VERSION ""

NS_ :

BS_:

BU_:

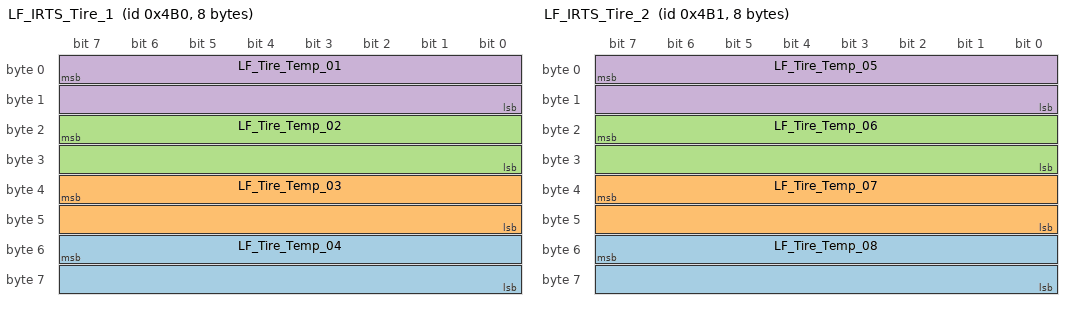
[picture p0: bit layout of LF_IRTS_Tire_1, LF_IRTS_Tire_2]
BO_ 1200 LF_IRTS_Tire_1: 8 Vector__XXX
 SG_ LF_Tire_Temp_04 : 55|16@0+ (0.1,-100) [-100|6453.5] "°C" Vector__XXX
 SG_ LF_Tire_Temp_03 : 39|16@0+ (0.1,-100) [-100|6453.5] "°C" Vector__XXX
 SG_ LF_Tire_Temp_02 : 23|16@0+ (0.1,-100) [-100|6453.5] "°C" Vector__XXX
 SG_ LF_Tire_Temp_01 : 7|16@0+ (0.1,-100) [-100|6453.5] "°C" Vector__XXX

BO_ 1201 LF_IRTS_Tire_2: 8 Vector__XXX
 SG_ LF_Tire_Temp_08 : 55|16@0+ (0.1,-100) [-100|6453.5] "°C" Vector__XXX
 SG_ LF_Tire_Temp_07 : 39|16@0+ (0.1,-100) [-100|6453.5] "°C" Vector__XXX
 SG_ LF_Tire_Temp_06 : 23|16@0+ (0.1,-100) [-100|6453.5] "°C" Vector__XXX
 SG_ LF_Tire_Temp_05 : 7|16@0+ (0.1,-100) [-100|6453.5] "°C" Vector__XXX

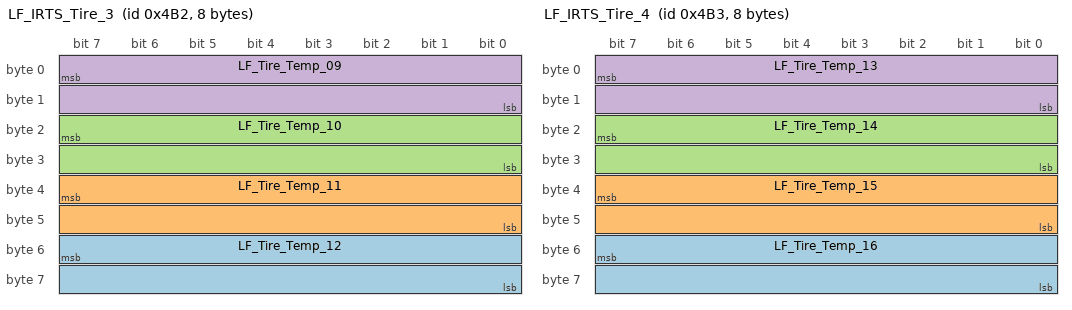
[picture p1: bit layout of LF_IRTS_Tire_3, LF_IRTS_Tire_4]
BO_ 1202 LF_IRTS_Tire_3: 8 Vector__XXX
 SG_ LF_Tire_Temp_12 : 55|16@0+ (0.1,-100) [-100|6453.5] "°C" Vector__XXX
 SG_ LF_Tire_Temp_11 : 39|16@0+ (0.1,-100) [-100|6453.5] "°C" Vector__XXX
 SG_ LF_Tire_Temp_10 : 23|16@0+ (0.1,-100) [-100|6453.5] "°C" Vector__XXX
 SG_ LF_Tire_Temp_09 : 7|16@0+ (0.1,-100) [-100|6453.5] "°C" Vector__XXX

BO_ 1203 LF_IRTS_Tire_4: 8 Vector__XXX
 SG_ LF_Tire_Temp_16 : 55|16@0+ (0.1,-100) [-100|6453.5] "°C" Vector__XXX
 SG_ LF_Tire_Temp_15 : 39|16@0+ (0.1,-100) [-100|6453.5] "°C" Vector__XXX
 SG_ LF_Tire_Temp_14 : 23|16@0+ (0.1,-100) [-100|6453.5] "°C" Vector__XXX
 SG_ LF_Tire_Temp_13 : 7|16@0+ (0.1,-100) [-100|6453.5] "°C" Vector__XXX

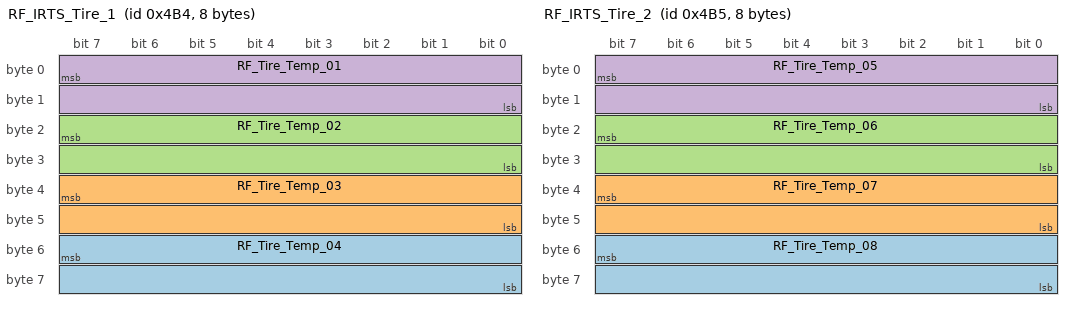
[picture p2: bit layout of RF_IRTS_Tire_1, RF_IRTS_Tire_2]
BO_ 1204 RF_IRTS_Tire_1: 8 Vector__XXX
 SG_ RF_Tire_Temp_04 : 55|16@0+ (0.1,-100) [-100|6453.5] "°C" Vector__XXX
 SG_ RF_Tire_Temp_03 : 39|16@0+ (0.1,-100) [-100|6453.5] "°C" Vector__XXX
 SG_ RF_Tire_Temp_02 : 23|16@0+ (0.1,-100) [-100|6453.5] "°C" Vector__XXX
 SG_ RF_Tire_Temp_01 : 7|16@0+ (0.1,-100) [-100|6453.5] "°C" Vector__XXX

BO_ 1205 RF_IRTS_Tire_2: 8 Vector__XXX
 SG_ RF_Tire_Temp_08 : 55|16@0+ (0.1,-100) [-100|6453.5] "°C" Vector__XXX
 SG_ RF_Tire_Temp_07 : 39|16@0+ (0.1,-100) [-100|6453.5] "°C" Vector__XXX
 SG_ RF_Tire_Temp_06 : 23|16@0+ (0.1,-100) [-100|6453.5] "°C" Vector__XXX
 SG_ RF_Tire_Temp_05 : 7|16@0+ (0.1,-100) [-100|6453.5] "°C" Vector__XXX

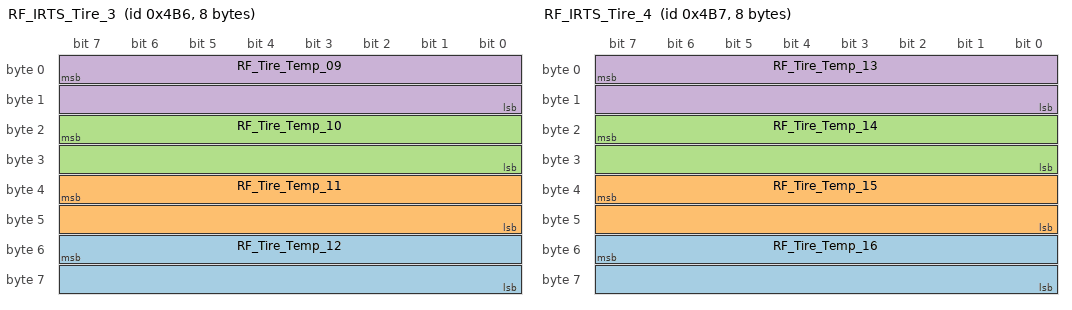
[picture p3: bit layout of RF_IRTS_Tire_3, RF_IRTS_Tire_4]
BO_ 1206 RF_IRTS_Tire_3: 8 Vector__XXX
 SG_ RF_Tire_Temp_12 : 55|16@0+ (0.1,-100) [-100|6453.5] "°C" Vector__XXX
 SG_ RF_Tire_Temp_11 : 39|16@0+ (0.1,-100) [-100|6453.5] "°C" Vector__XXX
 SG_ RF_Tire_Temp_10 : 23|16@0+ (0.1,-100) [-100|6453.5] "°C" Vector__XXX
 SG_ RF_Tire_Temp_09 : 7|16@0+ (0.1,-100) [-100|6453.5] "°C" Vector__XXX

BO_ 1207 RF_IRTS_Tire_4: 8 Vector__XXX
 SG_ RF_Tire_Temp_16 : 55|16@0+ (0.1,-100) [-100|6453.5] "°C" Vector__XXX
 SG_ RF_Tire_Temp_15 : 39|16@0+ (0.1,-100) [-100|6453.5] "°C" Vector__XXX
 SG_ RF_Tire_Temp_14 : 23|16@0+ (0.1,-100) [-100|6453.5] "°C" Vector__XXX
 SG_ RF_Tire_Temp_13 : 7|16@0+ (0.1,-100) [-100|6453.5] "°C" Vector__XXX

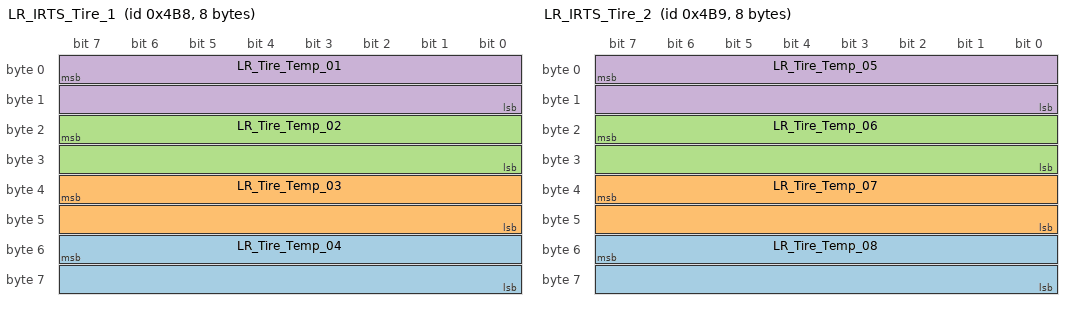
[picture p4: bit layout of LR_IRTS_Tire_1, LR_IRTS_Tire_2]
BO_ 1208 LR_IRTS_Tire_1: 8 Vector__XXX
 SG_ LR_Tire_Temp_04 : 55|16@0+ (0.1,-100) [-100|6453.5] "°C" Vector__XXX
 SG_ LR_Tire_Temp_03 : 39|16@0+ (0.1,-100) [-100|6453.5] "°C" Vector__XXX
 SG_ LR_Tire_Temp_02 : 23|16@0+ (0.1,-100) [-100|6453.5] "°C" Vector__XXX
 SG_ LR_Tire_Temp_01 : 7|16@0+ (0.1,-100) [-100|6453.5] "°C" Vector__XXX

BO_ 1209 LR_IRTS_Tire_2: 8 Vector__XXX
 SG_ LR_Tire_Temp_08 : 55|16@0+ (0.1,-100) [-100|6453.5] "°C" Vector__XXX
 SG_ LR_Tire_Temp_07 : 39|16@0+ (0.1,-100) [-100|6453.5] "°C" Vector__XXX
 SG_ LR_Tire_Temp_06 : 23|16@0+ (0.1,-100) [-100|6453.5] "°C" Vector__XXX
 SG_ LR_Tire_Temp_05 : 7|16@0+ (0.1,-100) [-100|6453.5] "°C" Vector__XXX

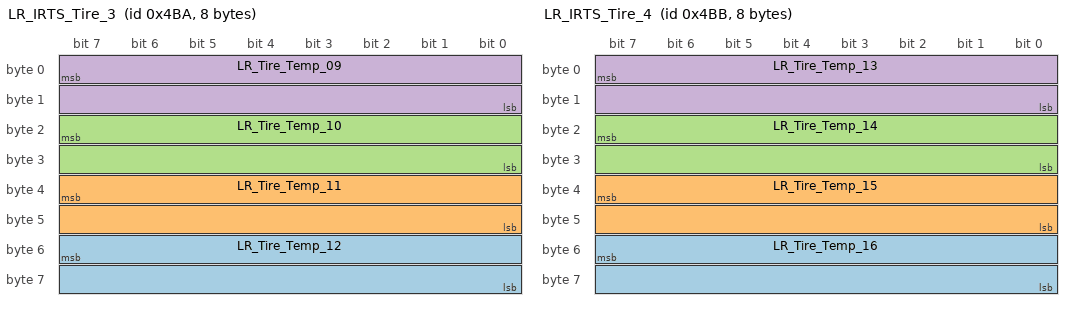
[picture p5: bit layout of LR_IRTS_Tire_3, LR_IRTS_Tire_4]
BO_ 1210 LR_IRTS_Tire_3: 8 Vector__XXX
 SG_ LR_Tire_Temp_12 : 55|16@0+ (0.1,-100) [-100|6453.5] "°C" Vector__XXX
 SG_ LR_Tire_Temp_11 : 39|16@0+ (0.1,-100) [-100|6453.5] "°C" Vector__XXX
 SG_ LR_Tire_Temp_10 : 23|16@0+ (0.1,-100) [-100|6453.5] "°C" Vector__XXX
 SG_ LR_Tire_Temp_09 : 7|16@0+ (0.1,-100) [-100|6453.5] "°C" Vector__XXX

BO_ 1211 LR_IRTS_Tire_4: 8 Vector__XXX
 SG_ LR_Tire_Temp_16 : 55|16@0+ (0.1,-100) [-100|6453.5] "°C" Vector__XXX
 SG_ LR_Tire_Temp_15 : 39|16@0+ (0.1,-100) [-100|6453.5] "°C" Vector__XXX
 SG_ LR_Tire_Temp_14 : 23|16@0+ (0.1,-100) [-100|6453.5] "°C" Vector__XXX
 SG_ LR_Tire_Temp_13 : 7|16@0+ (0.1,-100) [-100|6453.5] "°C" Vector__XXX

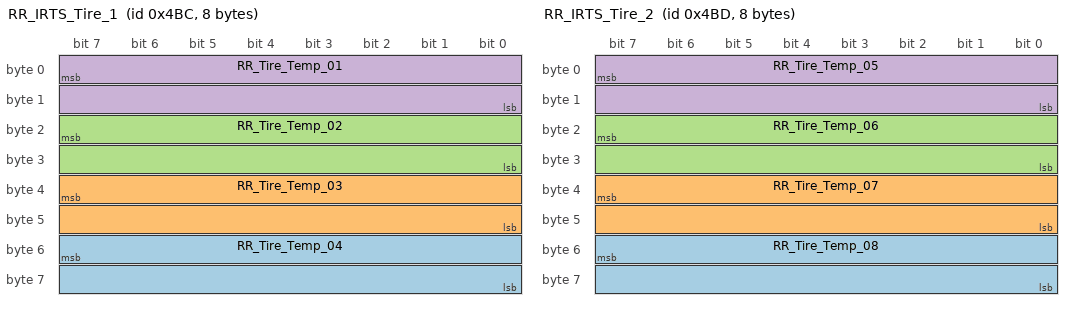
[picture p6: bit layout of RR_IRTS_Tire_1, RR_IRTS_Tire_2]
BO_ 1212 RR_IRTS_Tire_1: 8 Vector__XXX
 SG_ RR_Tire_Temp_04 : 55|16@0+ (0.1,-100) [-100|6453.5] "°C" Vector__XXX
 SG_ RR_Tire_Temp_03 : 39|16@0+ (0.1,-100) [-100|6453.5] "°C" Vector__XXX
 SG_ RR_Tire_Temp_02 : 23|16@0+ (0.1,-100) [-100|6453.5] "°C" Vector__XXX
 SG_ RR_Tire_Temp_01 : 7|16@0+ (0.1,-100) [-100|6453.5] "°C" Vector__XXX

BO_ 1213 RR_IRTS_Tire_2: 8 Vector__XXX
 SG_ RR_Tire_Temp_08 : 55|16@0+ (0.1,-100) [-100|6453.5] "°C" Vector__XXX
 SG_ RR_Tire_Temp_07 : 39|16@0+ (0.1,-100) [-100|6453.5] "°C" Vector__XXX
 SG_ RR_Tire_Temp_06 : 23|16@0+ (0.1,-100) [-100|6453.5] "°C" Vector__XXX
 SG_ RR_Tire_Temp_05 : 7|16@0+ (0.1,-100) [-100|6453.5] "°C" Vector__XXX

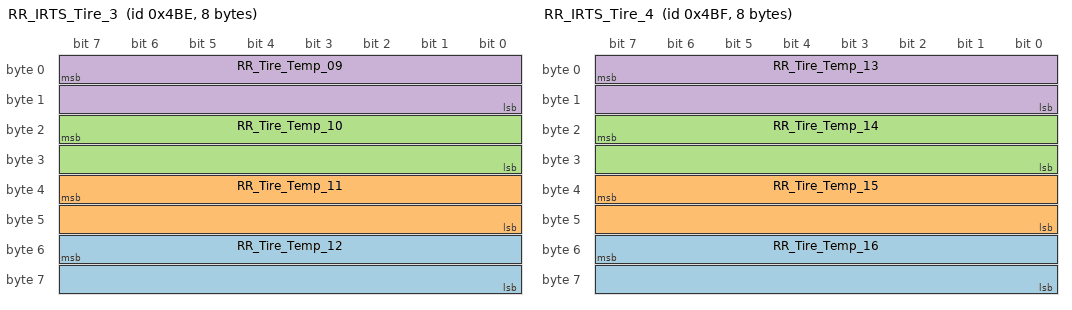
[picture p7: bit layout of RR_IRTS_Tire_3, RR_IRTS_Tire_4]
BO_ 1214 RR_IRTS_Tire_3: 8 Vector__XXX
 SG_ RR_Tire_Temp_12 : 55|16@0+ (0.1,-100) [-100|6453.5] "°C" Vector__XXX
 SG_ RR_Tire_Temp_11 : 39|16@0+ (0.1,-100) [-100|6453.5] "°C" Vector__XXX
 SG_ RR_Tire_Temp_10 : 23|16@0+ (0.1,-100) [-100|6453.5] "°C" Vector__XXX
 SG_ RR_Tire_Temp_09 : 7|16@0+ (0.1,-100) [-100|6453.5] "°C" Vector__XXX

BO_ 1215 RR_IRTS_Tire_4: 8 Vector__XXX
 SG_ RR_Tire_Temp_16 : 55|16@0+ (0.1,-100) [-100|6453.5] "°C" Vector__XXX
 SG_ RR_Tire_Temp_15 : 39|16@0+ (0.1,-100) [-100|6453.5] "°C" Vector__XXX
 SG_ RR_Tire_Temp_14 : 23|16@0+ (0.1,-100) [-100|6453.5] "°C" Vector__XXX
 SG_ RR_Tire_Temp_13 : 7|16@0+ (0.1,-100) [-100|6453.5] "°C" Vector__XXX

BA_DEF_ BO_  "GenMsgCycleTime" INT 0 0;
BA_DEF_DEF_  "GenMsgCycleTime" 0;
BA_ "GenMsgCycleTime" BO_ 1200 32;
BA_ "GenMsgCycleTime" BO_ 1201 32;
BA_ "GenMsgCycleTime" BO_ 1202 32;
BA_ "GenMsgCycleTime" BO_ 1203 32;
BA_ "GenMsgCycleTime" BO_ 1204 32;
BA_ "GenMsgCycleTime" BO_ 1205 32;
BA_ "GenMsgCycleTime" BO_ 1206 32;
BA_ "GenMsgCycleTime" BO_ 1207 32;
BA_ "GenMsgCycleTime" BO_ 1208 32;
BA_ "GenMsgCycleTime" BO_ 1209 32;
BA_ "GenMsgCycleTime" BO_ 1210 32;
BA_ "GenMsgCycleTime" BO_ 1211 32;
BA_ "GenMsgCycleTime" BO_ 1212 32;
BA_ "GenMsgCycleTime" BO_ 1213 32;
BA_ "GenMsgCycleTime" BO_ 1214 32;
BA_ "GenMsgCycleTime" BO_ 1215 32;
